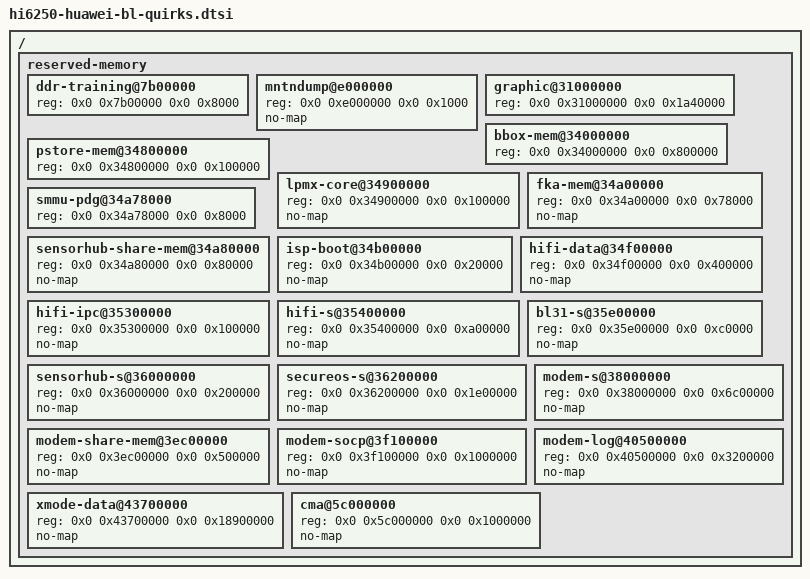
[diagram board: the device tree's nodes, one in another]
/ {
	reserved-memory {
		#address-cells = <2>;
		#size-cells = <2>;
		ranges;

		ddr-training@7b00000 {
			reg = <0x0 0x7b00000 0x0 0x8000>;
		};

		mntndump@e000000 {
			reg = <0x0 0xe000000 0x0 0x1000>;
			no-map;
		};

		graphic@31000000 {
			reg = <0x0 0x31000000 0x0 0x1a40000>;
		};

		bbox-mem@34000000 {
			reg = <0x0 0x34000000 0x0 0x800000>;
		};

		pstore-mem@34800000 {
			reg = <0x0 0x34800000 0x0 0x100000>;
		};

		lpmx-core@34900000 {
			reg = <0x0 0x34900000 0x0 0x100000>;
			no-map;
		};

		fka-mem@34a00000 {
			reg = <0x0 0x34a00000 0x0 0x78000>;
			no-map;
		};

		smmu-pdg@34a78000 {
			reg = <0x0 0x34a78000 0x0 0x8000>;
		};

		sensorhub-share-mem@34a80000 {
			reg = <0x0 0x34a80000 0x0 0x80000>;
			no-map;
		};

		isp-boot@34b00000 {
			reg = <0x0 0x34b00000 0x0 0x20000>;
			no-map;
		};

		hifi-data@34f00000 {
			reg = <0x0 0x34f00000 0x0 0x400000>;
			no-map;
		};

		hifi-ipc@35300000 {
			reg = <0x0 0x35300000 0x0 0x100000>;
			no-map;
		};

		hifi-s@35400000 {
			reg = <0x0 0x35400000 0x0 0xa00000>;
			no-map;
		};

		bl31-s@35e00000 {
			reg = <0x0 0x35e00000 0x0 0xc0000>;
			no-map;
		};

		sensorhub-s@36000000 {
			reg = <0x0 0x36000000 0x0 0x200000>;
			no-map;
		};

		secureos-s@36200000 {
			reg = <0x0 0x36200000 0x0 0x1e00000>;
			no-map;
		};

		modem-s@38000000 {
			reg = <0x0 0x38000000 0x0 0x6c00000>;
			no-map;
		};

		modem-share-mem@3ec00000 {
			reg = <0x0 0x3ec00000 0x0 0x500000>;
			no-map;
		};

		modem-socp@3f100000 {
			reg = <0x0 0x3f100000 0x0 0x1000000>;
			no-map;
		};

		modem-log@40500000 {
			reg = <0x0 0x40500000 0x0 0x3200000>;
			no-map;
		};

		xmode-data@43700000 {
			reg = <0x0 0x43700000 0x0 0x18900000>;
			no-map;
		};

		cma@5c000000 {
			reg = <0x0 0x5c000000 0x0 0x1000000>;
			no-map;
		};
	};
};
